# PIC32CX5109BZ31032 device description
Architecture: CORTEX-M4; Family: PIC32CX; Series: PIC32CXBZ31
Registers are 32-bit, read-write, reset 0x0 unless marked. A register's access mark holds for its fields unless they carry their own. Offsets are from the block's base; [hi:lo] are bit positions; {n}, {i} and the like mark numbered series; 'fields as' and 'values as' point back to an identical list.

## SysTick — System timer
Instances: SysTick 0xE000E010
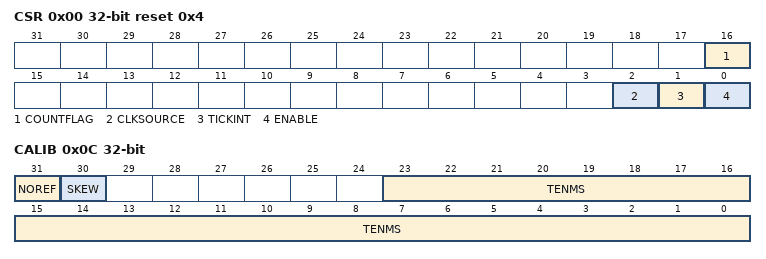
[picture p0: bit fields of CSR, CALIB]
0x00 CSR reset 0x4 — SysTick Control and Status Register
  [16] COUNTFLAG — Timer counted to 0 since last read of register
  [2] CLKSOURCE — Clock Source 0=external, 1=processor
    0=External clock; 1=Processor clock
  [1] TICKINT — SysTick Exception Request Enable
    0=Counting down to 0 does not assert the SysTick exception request; 1=Counting down to 0 asserts the SysTick exception request
  [0] ENABLE — SysTick Counter Enable
    0=Counter disabled; 1=Counter enabled
0x04 RVR reset not defined — SysTick Reload Value Register
  [23:0] RELOAD — Value to load into the SysTick Current Value Register when the counter reaches 0
0x08 CVR reset not defined — SysTick Current Value Register
  [23:0] CURRENT — Current value at the time the register is accessed
0x0C CALIB ro — SysTick Calibration Value Register
  [31] NOREF — No Separate Reference Clock
    0=The reference clock is provided; 1=The reference clock is not provided
  [30] SKEW — TENMS is rounded from non-integer ratio
    0=10ms calibration value is exact; 1=10ms calibration value is inexact, because of the clock frequency
  [23:0] TENMS — Reload value to use for 10ms timing

## TPI — Trace Port Interface Register
Instances: TPI 0xE0040000
0x00 SSPSR ro reset not defined — Supported Parallel Port Size Register
0x04 CSPSR reset not defined — Current Parallel Port Size Register
0x10 ACPR reset not defined — Asynchronous Clock Prescaler Register
  [12:0] PRESCALER
0xF0 SPPR reset not defined — Selected Pin Protocol Register
  [1:0] TXMODE
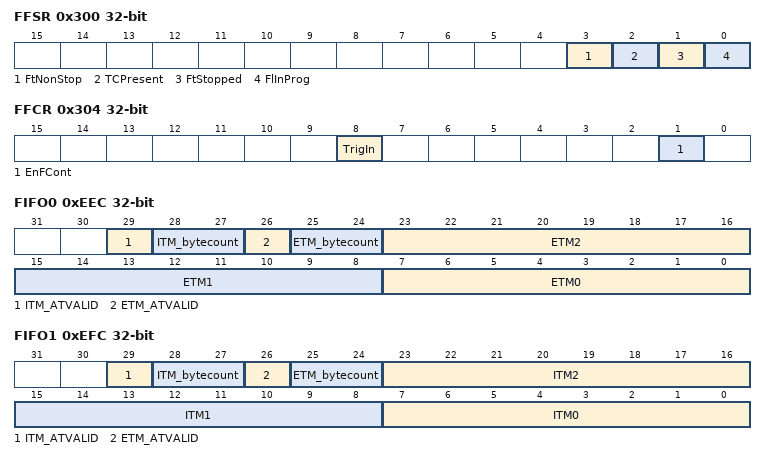
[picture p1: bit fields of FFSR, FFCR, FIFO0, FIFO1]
0x300 FFSR ro reset not defined — Formatter and Flush Status Register
  [3] FtNonStop, [2] TCPresent, [1] FtStopped, [0] FlInProg
0x304 FFCR reset not defined — Formatter and Flush Control Register
  [8] TrigIn, [1] EnFCont
0x308 FSCR ro reset not defined — Formatter Synchronization Counter Register
0xEE8 TRIGGER ro reset not defined
  [0] TRIGGER
0xEEC FIFO0 ro reset not defined — Integration ETM Data
  [29] ITM_ATVALID, [28:27] ITM_bytecount, [26] ETM_ATVALID, [25:24] ETM_bytecount, [23:16] ETM2, [15:8] ETM1, [7:0] ETM0
0xEF0 ITATBCTR2 ro reset not defined
  [0] ATREADY
0xEF8 ITATBCTR0 ro reset not defined
  [0] ATREADY
0xEFC FIFO1 ro reset not defined — Integration ITM Data
  [29] ITM_ATVALID, [28:27] ITM_bytecount, [26] ETM_ATVALID, [25:24] ETM_bytecount, [23:16] ITM2, [15:8] ITM1, [7:0] ITM0
0xF00 ITCTRL reset not defined — Integration Mode Control
  [0] Mode
0xFA0 CLAIMSET reset not defined (atomic set) — Claim tag set
0xFA4 CLAIMCLR reset not defined (atomic clear) — Claim tag clear
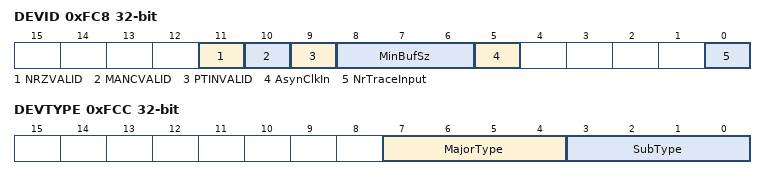
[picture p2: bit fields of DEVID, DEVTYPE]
0xFC8 DEVID ro reset not defined — TPIU_DEVID
  [11] NRZVALID, [10] MANCVALID, [9] PTINVALID, [8:6] MinBufSz, [5] AsynClkIn, [0] NrTraceInput
0xFCC DEVTYPE ro reset not defined — TPIU_DEVTYPE
  [7:4] MajorType, [3:0] SubType

## AC — Analog Comparators
Instances: AC 0x42001C00
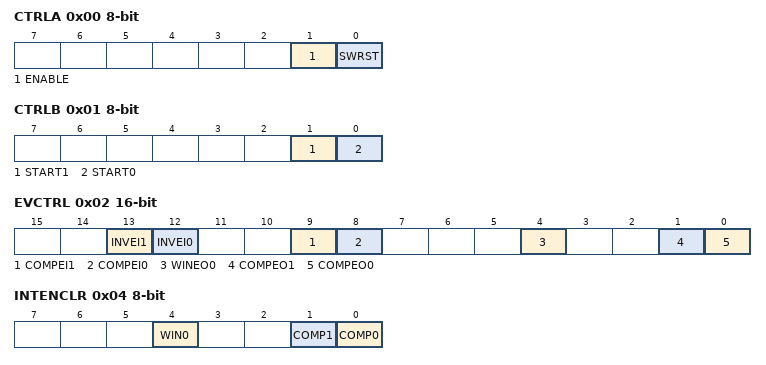
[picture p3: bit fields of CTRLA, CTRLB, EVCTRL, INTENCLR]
0x00 CTRLA 8-bit (WSYNC) — Control A
  [1] ENABLE
  [0] SWRST — Software Reset
0x01 CTRLB 8-bit wo — Control B
  [1] START1 — Comparator 1 Start Comparison
  [0] START0 — Comparator 0 Start Comparison
0x02 EVCTRL 16-bit — Event Control
  [13] INVEI1 — Comparator 1 Input Event Invert Enable
  [12] INVEI0 — Comparator 0 Input Event Invert Enable
  [9] COMPEI1 — Comparator 1 Event Input Enable
  [8] COMPEI0 — Comparator 0 Event Input Enable
  [4] WINEO0 — Window 0 Event Output Enable
  [1] COMPEO1 — Comparator 1 Event Output Enable
  [0] COMPEO0 — Comparator 0 Event Output Enable
0x04 INTENCLR 8-bit (atomic clear) — Interrupt Enable Clear
  [4] WIN0 — Window 0 Interrupt Enable
  [1] COMP1 — Comparator 1 Interrupt Enable
  [0] COMP0 — Comparator 0 Interrupt Enable
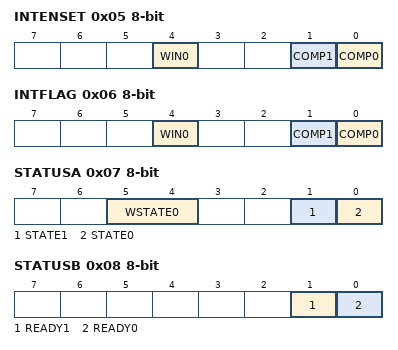
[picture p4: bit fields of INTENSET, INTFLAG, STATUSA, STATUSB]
0x05 INTENSET 8-bit (atomic set) — Interrupt Enable Set
  fields as INTENCLR
0x06 INTFLAG 8-bit (atomic clear) — Interrupt Flag Status and Clear
  [4] WIN0 — Window 0
  [1] COMP1 — Comparator 1
  [0] COMP0 — Comparator 0
0x07 STATUSA 8-bit ro
  [5:4] WSTATE0 — Window 0 Current State
    0=ABOVE (Signal is above window); 1=INSIDE (Signal is inside window); 2=BELOW (Signal is below window)
  [1] STATE1 — Comparator 1 Current State
  [0] STATE0 — Comparator 0 Current State
0x08 STATUSB 8-bit ro
  [1] READY1 — Comparator 1 Ready
  [0] READY0 — Comparator 0 Ready
0x09 DBGCTRL 8-bit — Debug Control
  [0] DBGRUN — Debug Run
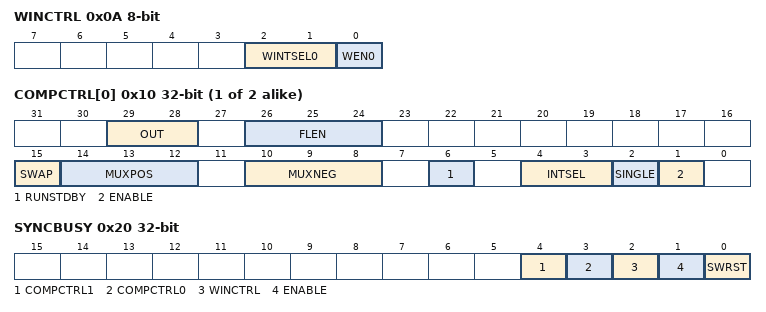
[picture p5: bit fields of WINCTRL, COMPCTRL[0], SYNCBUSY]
0x0A WINCTRL 8-bit (WSYNC) — Window Control
  [2:1] WINTSEL0 — Window 0 Interrupt Selection
    0=ABOVE (Interrupt on signal above window); 1=INSIDE (Interrupt on signal inside window); 2=BELOW (Interrupt on signal below window); 3=OUTSIDE (Interrupt on signal outside window)
  [0] WEN0 — Window 0 Mode Enable
{0xC+i} SCALER[{i}] (i=0..1) 8-bit — Scaler n
  [5:0] VALUE — Scaler Value
{0x10+4i} COMPCTRL[{i}] (i=0..1) — Comparator Control n
  [29:28] OUT — Output
    0=OFF (The output of COMPn is not routed to the COMPn I/O port); 1=ASYNC (The asynchronous output of COMPn is routed to the COMPn I/O port); 2=SYNC (The synchronous output (including filtering) of COMPn is routed to the COMPn I/O port)
  [26:24] FLEN — Filter Length
    0=OFF (No filtering); 1=MAJ3 (3-bit majority function (2 of 3)); 2=MAJ5 (5-bit majority function (3 of 5))
  [15] SWAP — Swap Inputs and Invert
  [14:12] MUXPOS — Positive Input Mux Selection
    {v}=PIN{v} (I/O pin {v}) (v=0..3); 4=VSCALE (VDD Scaler)
  [10:8] MUXNEG — Negative Input Mux Selection
    {v}=PIN{v} (I/O pin {v}) (v=0..3); 4=GND (Ground); 5=VSCALE (VDD scaler); 6=BANDGAP (Internal bandgap voltage); 7=DAC (DAC output)
  [6] RUNSTDBY — Run in Standby
  [4:3] INTSEL — Interrupt Selection
    0=TOGGLE (Interrupt on comparator output toggle); 1=RISING (Interrupt on comparator output rising); 2=FALLING (Interrupt on comparator output falling); 3=EOC (Interrupt on end of comparison (single-shot mode only))
  [2] SINGLE — Single-Shot Mode
  [1] ENABLE
0x20 SYNCBUSY ro — Synchronization Busy
  [4] COMPCTRL1 — COMPCTRL 1 Synchronization Busy
  [3] COMPCTRL0 — COMPCTRL 0 Synchronization Busy
  [2] WINCTRL — WINCTRL Synchronization Busy
  [1] ENABLE — Enable Synchronization Busy
  [0] SWRST — Software Reset Synchronization Busy
